# RP2040 register map
Vendor: Raspberry Pi; File version: 2025.06.15
CPU: CM0PLUS r0p1, little endian, 2 interrupt priority bits
Registers are 32-bit, read-write, no defined reset value unless marked. A register's access mark holds for its fields unless they carry their own. Offsets are from the block's base; [hi:lo] are bit positions.

## XIP_SSI — DW_apb_ssi has the following features: * APB interface – Allows for easy integration into a DesignWare Synthesizable Components for AMBA 2 implementation. * APB3 and APB4 protocol support. * Scalable APB data bus width – Supports APB data bus widths of 8, 16, and 32 bits. * Serial-master or serial-slave operation – Enables serial communication with serial-master or serial-slave peripheral devices. * Programmable Dual/Quad/Octal SPI support in Master Mode. * Dual Data Rate (DDR) and Read Data Strobe (RDS) Support - Enables the DW_apb_ssi master to perform operations with the device in DDR and RDS modes when working in Dual/Quad/Octal mode of operation. * Data Mask Support - Enables the DW_apb_ssi to selectively update the bytes in the device. This feature is applicable only in enhanced SPI modes. * eXecute-In-Place (XIP) support - Enables the DW_apb_ssi master to behave as a memory mapped I/O and fetches the data from the device based on the APB read request. This feature is applicable only in enhanced SPI modes. * DMA Controller Interface – Enables the DW_apb_ssi to interface to a DMA controller over the bus using a handshaking interface for transfer requests. * Independent masking of interrupts – Master collision, transmit FIFO overflow, transmit FIFO empty, receive FIFO full, receive FIFO underflow, and receive FIFO overflow interrupts can all be masked independently. * Multi-master contention detection – Informs the processor of multiple serial-master accesses on the serial bus. * Bypass of meta-stability flip-flops for synchronous clocks – When the APB clock (pclk) and the DW_apb_ssi serial clock (ssi_clk) are synchronous, meta-stable flip-flops are not used when transferring control signals across these clock domains. * Programmable delay on the sample time of the received serial data bit (rxd) enables programmable control of routing delays resulting in higher serial data-bit rates. * Programmable features: - Serial interface operation – Choice of Motorola SPI, Texas Instruments Synchronous Serial Protocol or National Semiconductor Microwire. - Clock bit-rate – Dynamic control of the serial bit rate of the data transfer used in only serial-master mode of operation. - Data Item size (4 to 32 bits) – Item size of each data transfer under the control of the programmer. * Configured features: - FIFO depth – 16 words deep. The FIFO width is fixed at 32 bits. - 1 slave select output. - Hardware slave-select – Dedicated hardware slave-select line. - Combined interrupt line - one combined interrupt line from the DW_apb_ssi to the interrupt controller. - Interrupt polarity – active high interrupt lines. - Serial clock polarity – low serial-clock polarity directly after reset. - Serial clock phase – capture on first edge of serial-clock directly after reset.
Base 0x18000000
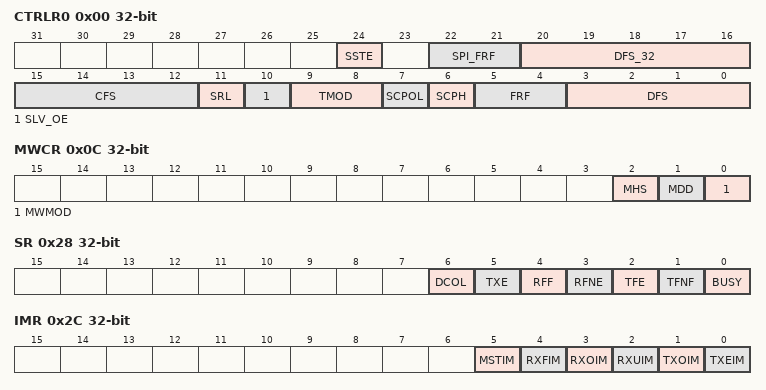
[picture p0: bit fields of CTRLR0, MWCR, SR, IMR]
0x00 CTRLR0 — Control register 0
  [24] SSTE — Slave select toggle enable
  [22:21] SPI_FRF — SPI frame format
    0=STD (Standard 1-bit SPI frame format 1 bit per SCK, full-duplex); 1=DUAL (Dual-SPI frame format two bits per SCK, half-duplex); 2=QUAD (Quad-SPI frame format four bits per SCK, half-duplex)
  [20:16] DFS_32 — Data frame size in 32b transfer mode Value of n -> n+1 clocks per frame.
  [15:12] CFS — Control frame size Value of n -> n+1 clocks per frame.
  [11] SRL — Shift register loop (test mode)
  [10] SLV_OE — Slave output enable
  [9:8] TMOD — Transfer mode
    0=TX_AND_RX (Both transmit and receive); 1=TX_ONLY (Transmit only (not for FRF == 0, standard SPI mode)); 2=RX_ONLY (Receive only (not for FRF == 0, standard SPI mode)); 3=EEPROM_READ (EEPROM read mode (TX then RX RX starts after control data TX'd))
  [7] SCPOL — Serial clock polarity
  [6] SCPH — Serial clock phase
  [5:4] FRF — Frame format
  [3:0] DFS — Data frame size
0x04 CTRLR1 — Master Control register 1
  [15:0] NDF — Number of data frames
0x08 SSIENR — SSI Enable
  [0] SSI_EN — SSI enable
0x0C MWCR — Microwire Control
  [2] MHS — Microwire handshaking
  [1] MDD — Microwire control
  [0] MWMOD — Microwire transfer mode
0x10 SER — Slave enable
  [0] SER — For each bit: 0 -> slave not selected 1 -> slave selected
0x14 BAUDR — Baud rate
  [15:0] SCKDV — SSI clock divider
0x18 TXFTLR — TX FIFO threshold level
  [7:0] TFT — Transmit FIFO threshold
0x1C RXFTLR — RX FIFO threshold level
  [7:0] RFT — Receive FIFO threshold
0x20 TXFLR — TX FIFO level
  [7:0] TFTFL ro — Transmit FIFO level
0x24 RXFLR — RX FIFO level
  [7:0] RXTFL ro — Receive FIFO level
0x28 SR — Status register
  [6] DCOL ro — Data collision error
  [5] TXE ro — Transmission error
  [4] RFF ro — Receive FIFO full
  [3] RFNE ro — Receive FIFO not empty
  [2] TFE ro — Transmit FIFO empty
  [1] TFNF ro — Transmit FIFO not full
  [0] BUSY ro — SSI busy flag
0x2C IMR — Interrupt mask
  [5] MSTIM — Multi-master contention interrupt mask
  [4] RXFIM — Receive FIFO full interrupt mask
  [3] RXOIM — Receive FIFO overflow interrupt mask
  [2] RXUIM — Receive FIFO underflow interrupt mask
  [1] TXOIM — Transmit FIFO overflow interrupt mask
  [0] TXEIM — Transmit FIFO empty interrupt mask
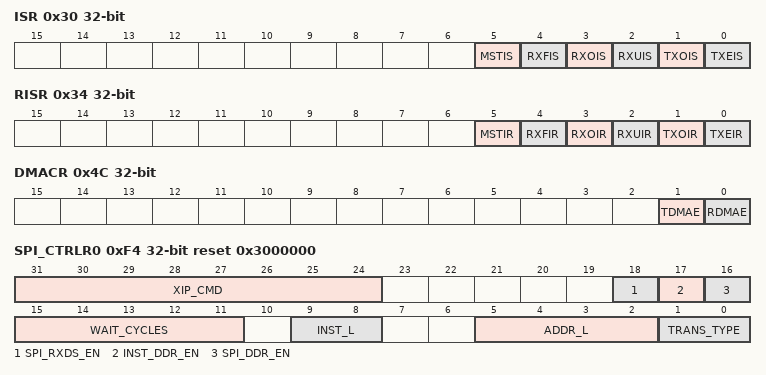
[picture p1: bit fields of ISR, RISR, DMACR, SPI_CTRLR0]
0x30 ISR — Interrupt status
  [5] MSTIS ro — Multi-master contention interrupt status
  [4] RXFIS ro — Receive FIFO full interrupt status
  [3] RXOIS ro — Receive FIFO overflow interrupt status
  [2] RXUIS ro — Receive FIFO underflow interrupt status
  [1] TXOIS ro — Transmit FIFO overflow interrupt status
  [0] TXEIS ro — Transmit FIFO empty interrupt status
0x34 RISR — Raw interrupt status
  [5] MSTIR ro — Multi-master contention raw interrupt status
  [4] RXFIR ro — Receive FIFO full raw interrupt status
  [3] RXOIR ro — Receive FIFO overflow raw interrupt status
  [2] RXUIR ro — Receive FIFO underflow raw interrupt status
  [1] TXOIR ro — Transmit FIFO overflow raw interrupt status
  [0] TXEIR ro — Transmit FIFO empty raw interrupt status
0x38 TXOICR — TX FIFO overflow interrupt clear
  [0] TXOICR ro — Clear-on-read transmit FIFO overflow interrupt
0x3C RXOICR — RX FIFO overflow interrupt clear
  [0] RXOICR ro — Clear-on-read receive FIFO overflow interrupt
0x40 RXUICR — RX FIFO underflow interrupt clear
  [0] RXUICR ro — Clear-on-read receive FIFO underflow interrupt
0x44 MSTICR — Multi-master interrupt clear
  [0] MSTICR ro — Clear-on-read multi-master contention interrupt
0x48 ICR — Interrupt clear
  [0] ICR ro — Clear-on-read all active interrupts
0x4C DMACR — DMA control
  [1] TDMAE — Transmit DMA enable
  [0] RDMAE — Receive DMA enable
0x50 DMATDLR — DMA TX data level
  [7:0] DMATDL — Transmit data watermark level
0x54 DMARDLR — DMA RX data level
  [7:0] DMARDL — Receive data watermark level (DMARDLR+1)
0x58 IDR reset 0x51535049 (reset mask 0x0) — Identification register
  [31:0] IDCODE ro — Peripheral dentification code
0x5C SSI_VERSION_ID reset 0x3430312A (reset mask 0x0) — Version ID
  [31:0] SSI_COMP_VERSION ro — SNPS component version (format X.YY)
0x60 DR0 — Data Register 0 (of 36)
  [31:0] DR — First data register of 36
0xF0 RX_SAMPLE_DLY — RX sample delay
  [7:0] RSD — RXD sample delay (in SCLK cycles)
0xF4 SPI_CTRLR0 reset 0x3000000 (reset mask 0x0) — SPI control
  [31:24] XIP_CMD — SPI Command to send in XIP mode (INST_L = 8-bit) or to append to Address (INST_L = 0-bit)
  [18] SPI_RXDS_EN — Read data strobe enable
  [17] INST_DDR_EN — Instruction DDR transfer enable
  [16] SPI_DDR_EN — SPI DDR transfer enable
  [15:11] WAIT_CYCLES — Wait cycles between control frame transmit and data reception (in SCLK cycles)
  [9:8] INST_L — Instruction length (0/4/8/16b)
    0=NONE (No instruction); 1=4B (4-bit instruction); 2=8B (8-bit instruction); 3=16B (16-bit instruction)
  [5:2] ADDR_L — Address length (0b-60b in 4b increments)
  [1:0] TRANS_TYPE — Address and instruction transfer format
    0=1C1A (Command and address both in standard SPI frame format); 1=1C2A (Command in standard SPI format, address in format specified by FRF); 2=2C2A (Command and address both in format specified by FRF (e.g. Dual-SPI))
0xF8 TXD_DRIVE_EDGE — TX drive edge
  [7:0] TDE — TXD drive edge
